# G32F031 register map
File version: 1.0
CPU: CM0PLUS r0p1, little endian, no MPU, no FPU, 2 interrupt priority bits
Registers are 32-bit, read-write, reset 0x0 unless marked. A register's access mark holds for its fields unless they carry their own. Offsets are from the block's base; [hi:lo] are bit positions; lines under a group give offsets from that group; {n}, {i} and the like mark numbered series.

## ADC — Analog-to-digital converter
Base 0x40005400
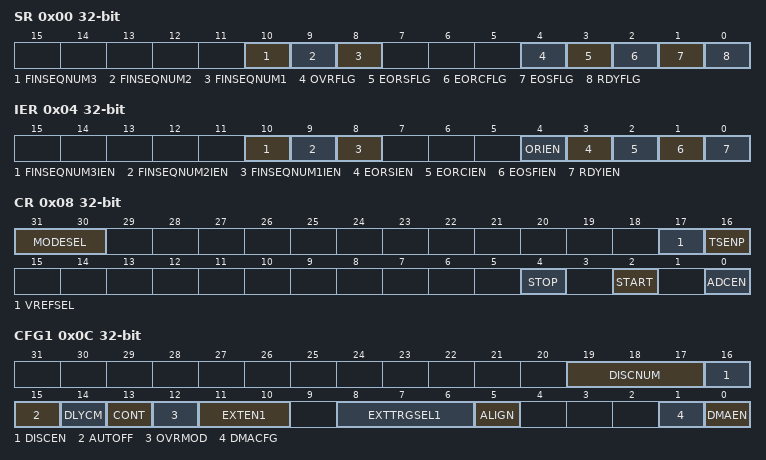
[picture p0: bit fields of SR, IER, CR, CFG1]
0x00 SR — ADC interrupt and status register
  [10] FINSEQNUM3 — NUM.3 of Sequential Section Sampling Finish
  [9] FINSEQNUM2 — NUM.2 of Sequential Section Sampling Finish
  [8] FINSEQNUM1 — NUM.1 of Sequential Section Sampling Finish
  [4] OVRFLG — ADC group regular overrun flag
  [3] EORSFLG — ADC group regular end of sequence conversions flag
  [2] EORCFLG — ADC group regular end of unitary conversion flag
  [1] EOSFLG — ADC group regular end of sampling flag
  [0] RDYFLG — ADC Ready Flag
0x04 IER — ADC interrupt enable register
  [10] FINSEQNUM3IEN — NUM.3 of Sequential Section Sampling Finish interrupt
  [9] FINSEQNUM2IEN — NUM.2 of Sequential Section Sampling Finish interrupt
  [8] FINSEQNUM1IEN — NUM.1 of Sequential Section Sampling Finish interrupt
  [4] ORIEN — ADC group regular overrun interrupt
  [3] EORSIEN — ADC group regular end of sequence conversions interrupt
  [2] EORCIEN — ADC group regular end of unitary conversion interrupt
  [1] EOSFIEN — ADC group regular end of sampling interrupt
  [0] RDYIEN — ADC Ready Interrupt Enable
0x08 CR — ADC control register
  [31:30] MODESEL — ADC Work Mode Selection
  [17] VREFSEL — ADC group injected conversion stop
  [16] TSENP — /
  [4] STOP — ADC group regular conversion stop
  [2] START — ADC group regular conversion start
  [0] ADCEN — ADC enable
0x0C CFG1 — ADC configuration register 1
  [19:17] DISCNUM — Discontinuous mode channel count
  [16] DISCEN — Discontinuous mode for regular channels
  [15] AUTOFF — Auto-Off Mode Enable
  [14] DLYCM — Delayed conversion mode
  [13] CONT — Single/continuous conversion mode for regular conversions
  [12] OVRMOD — Overrun Mode
  [11:10] EXTEN1 — ADC group regular external trigger polarity
  [8:6] EXTTRGSEL1 — ADC group regular external trigger source
  [5] ALIGN — Data alignment
  [1] DMACFG — ADC DMA transfer configuration
  [0] DMAEN — ADC DMA transfer enable
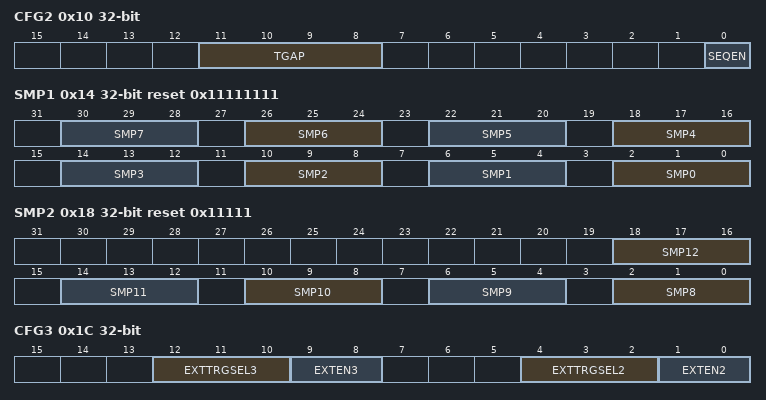
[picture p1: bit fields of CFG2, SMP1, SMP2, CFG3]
0x10 CFG2 — ADC configuration register 2
  [11:8] TGAP — Time of The Gap between Conversions in Sequential Section Configure
  [0] SEQEN — Sequential Section Sampling Enable
0x14 SMP1 reset 0x11111111 — ADC sampling time register 1
  [4n+2:4n] SMP{n} (n=0..7) — ADC channel {n} sampling time selection
0x18 SMP2 reset 0x11111 — ADC sampling time register 2
  [4n-30:4n-32] SMP{n} (n=8..12) — ADC channel {n} sampling time selection
0x1C CFG3 — ADC configuration register 3
  [12:10] EXTTRGSEL3 — External trigger selection for regular group
  [9:8] EXTEN3 — External trigger enable and polarity selection for regular channels
  [4:2] EXTTRGSEL2 — External trigger selection for regular group
  [1:0] EXTEN2 — External trigger enable and polarity selection for regular channels
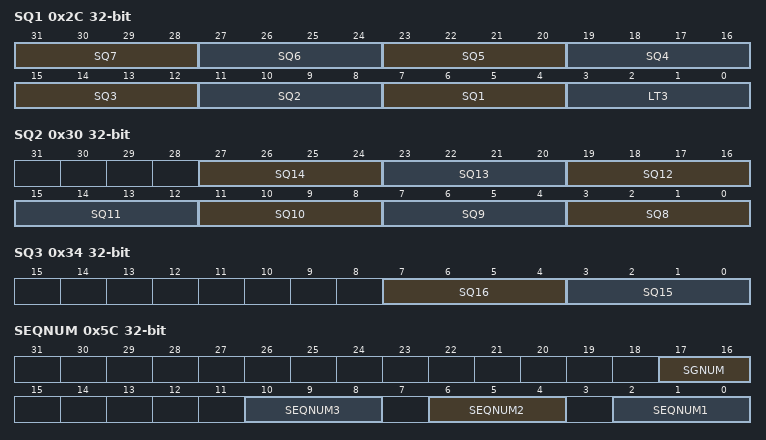
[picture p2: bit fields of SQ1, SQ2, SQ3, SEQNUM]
0x2C SQ1 — ADC group regular sequencer register 1
  [4n+3:4n] SQ{n} (n=1..7) — ADC group regular sequencer rank {n}
  [3:0] LT3 — ADC group regular sequencer scan length
0x30 SQ2 — ADC group regular sequencer register 2
  [4n-29:4n-32] SQ{n} (n=8..14) — ADC group regular sequencer rank {n}
0x34 SQ3 — ADC group regular sequencer register 3
  [7:4] SQ16 — ADC group regular sequencer rank 16
  [3:0] SQ15 — ADC group regular sequencer rank 15
0x38 DR ro — ADC group regular data register
  [15:0] RDATA — ADC group regular conversion data
{0x3C+4i} DR{i} ro (i=0..5) — Segmented sampling result data {i}
  [15:0] SDATA{i} — Sequence Segmentation Sampling Result Data
0x54 DR6 ro — Segmented sampling 6
  [15:0] SDATA6 — Sequence Segmentation Sampling Result Data
0x58 DR7 ro — Segmented sampling result data 7
  [15:0] SDATA7 — Sequence Segmentation Sampling Result Data
0x5C SEQNUM — The Number of Sequencial Section
  [17:16] SGNUM — The Number of Sequencial Section
  [10:8] SEQNUM3 — Section3 Transmission Time Setup
  [6:4] SEQNUM2 — Section2 Transmission Time Setup
  [2:0] SEQNUM1 — Section1 Transmission Time Setup
